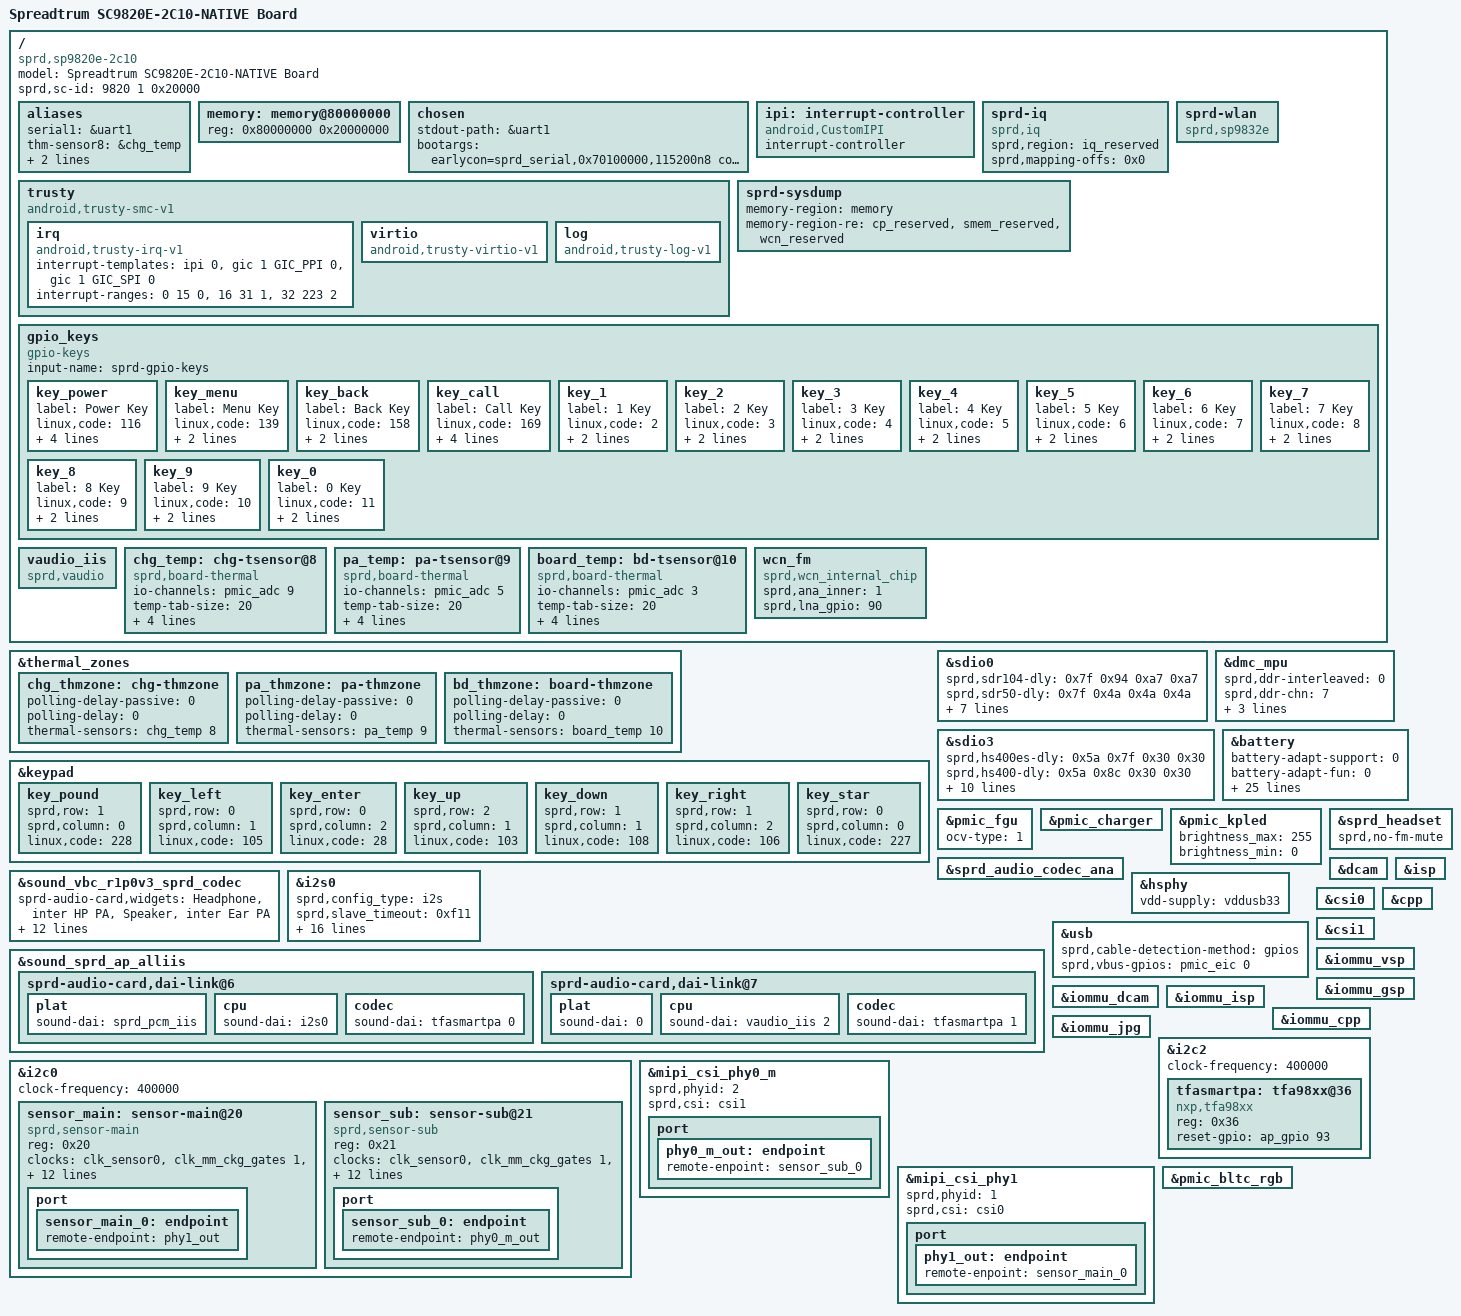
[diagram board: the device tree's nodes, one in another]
/*
 * Spreadtrum sharkle sp9820e board DTS file
 *
 * Copyright (C) 2017, Spreadtrum Communications Inc.
 *
 * This file is licensed under a dual GPLv2 or X11 license.
 */
/dts-v1/;

#include "sc9820e.dtsi"
#include "sp9820e-common.dtsi"

/ {
	model = "Spreadtrum SC9820E-2C10-NATIVE Board";

	compatible = "sprd,sp9820e-2c10", "sprd,sc9820e";

	sprd,sc-id = <9820 1 0x20000>;

	aliases {
		serial1 = &uart1;
		thm-sensor8 = &chg_temp;
		thm-sensor9 = &pa_temp;
		thm-sensor10 = &board_temp;
	};

	memory: memory@80000000 {
		device_type = "memory";
		reg = <0x80000000 0x20000000>;
	};

	chosen {
		stdout-path = &uart1;
		bootargs = "earlycon=sprd_serial,0x70100000,115200n8 console=ttyS1,115200n8 loglevel=1 init=/init root=/dev/ram0 rw androidboot.hardware=sp9820e_2c10";
	};

	ipi: interrupt-controller {
		compatible = "android,CustomIPI";
		#interrupt-cells = <1>;
		interrupt-controller;
	};

	trusty {
		compatible = "android,trusty-smc-v1";

		irq {
			compatible = "android,trusty-irq-v1";
			interrupt-templates = <&ipi 0>,
						<&gic 1 GIC_PPI 0>,
						<&gic 1 GIC_SPI 0>;
			interrupt-ranges = < 0  15 0>,
						<16  31 1>,
						<32 223 2>;
		};

		virtio {
			compatible = "android,trusty-virtio-v1";
		};

		log {
			compatible = "android,trusty-log-v1";
		};
	};

	sprd-iq {
		compatible = "sprd,iq";
		sprd,region = <&iq_reserved>;
		sprd,mapping-offs = <0x0>;
	};

	sprd-sysdump {
		memory-region = <&memory>;
		memory-region-re = <&cp_reserved>, <&smem_reserved>,
				   <&wcn_reserved>;
	};

	sprd-wlan {
		 compatible = "sprd,sp9832e";
	};

	gpio_keys {
		compatible = "gpio-keys";
		input-name = "sprd-gpio-keys";
		status = "ok";

		key_power {
			label = "Power Key";
			linux,code = <116>;
			gpios = <&pmic_eic 1 1>;
			debounce-interval = <5>;
			gpio-key,wakeup;
			gpio-key,level-trigger;
		};
		key_menu {
			label = "Menu Key";
			linux,code = <139>;
			gpios = <&ap_gpio 63 1>;
			gpio-key,wakeup;
		};
	
		key_back {
			label = "Back Key";
			linux,code = <158>;
			gpios = <&ap_gpio 145 1>;
			gpio-key,wakeup;
		};

		key_call {
			label = "Call Key";
			linux,code = <169>;
			gpios = <&pmic_eic 10 0>;
			debounce-interval = <5>;
			gpio-key,wakeup;
			gpio-key,level-trigger;
		};
		
		key_1 {
			label = "1 Key";
			linux,code = <2>;
			gpios = <&ap_gpio 72 1>;
			gpio-key,wakeup;
		};
		key_2 {
			label = "2 Key";
			linux,code = <3>;
			gpios = <&ap_gpio 156 1>;
			gpio-key,wakeup;
		};
		key_3 {
			label = "3 Key";
			linux,code = <4>;
			gpios = <&ap_gpio 144 1>;
			gpio-key,wakeup;
		};
		key_4 {
			label = "4 Key";
			linux,code = <5>;
			gpios = <&ap_gpio 73 1>;
			gpio-key,wakeup;
		};
		key_5 {
			label = "5 Key";
			linux,code = <6>;
			gpios = <&ap_gpio 154 1>;
			gpio-key,wakeup;
		};
	
		key_6 {
			label = "6 Key";
			linux,code = <7>;
			gpios = <&ap_gpio 4 1>;
			gpio-key,wakeup;
		};
		key_7 {
			label = "7 Key";
			linux,code = <8>;
			gpios = <&ap_gpio 138 1>;
			gpio-key,wakeup;
		};
		key_8 {
			label = "8 Key";
			linux,code = <9>;
			gpios = <&ap_gpio 155 1>;
			gpio-key,wakeup;
		};
		key_9 {
			label = "9 Key";
			linux,code = <10>;
			gpios = <&ap_gpio 5 1>;
			gpio-key,wakeup;
		};
		key_0 {
			label = "0 Key";
			linux,code = <11>;
			gpios = <&ap_gpio 137 1>;
			gpio-key,wakeup;
		};

	};

	vaudio_iis: vaudio_iis {
		compatible = "sprd,vaudio";
		#sound-dai-cells = <1>;
	};

	chg_temp:chg-tsensor@8 {
		compatible = "sprd,board-thermal";
		#thermal-sensor-cells = <1>;
		io-channels = <&pmic_adc 9>;
		io-channel-names = "adc_temp";
		temp-tab-size = <20>;
		temp-tab-val = <1094 1074 1050 1020 983 941 892
				838 779 717 654 590 528 468 413 362
				316 274 238 206>;
		temp-tab-temp = <750 800 850 900 950 1000 1050 1100
				 1150 1200 1250 1300 1350 1400 1450 1500
				 1550 1600 1650 1700>;
	};

	pa_temp:pa-tsensor@9 {
		compatible = "sprd,board-thermal";
		#thermal-sensor-cells = <1>;
		io-channels = <&pmic_adc 5>;
		io-channel-names = "adc_temp";
		temp-tab-size = <20>;
		temp-tab-val = <1094 1074 1050 1020 983 941 892
				838 779 717 654 590 528 468 413 362
				316 274 238 206>;
		temp-tab-temp = <750 800 850 900 950 1000 1050 1100
				 1150 1200 1250 1300 1350 1400 1450 1500
				 1550 1600 1650 1700>;
	};

	board_temp:bd-tsensor@10 {
		compatible = "sprd,board-thermal";
		#thermal-sensor-cells = <1>;
		io-channels = <&pmic_adc 3>;
		io-channel-names = "adc_temp";
		temp-tab-size = <20>;
		temp-tab-val = <1094 1074 1050 1020 983 941 892
				838 779 717 654 590 528 468 413 362
				316 274 238 206>;
		temp-tab-temp = <750 800 850 900 950 1000 1050 1100
				 1150 1200 1250 1300 1350 1400 1450 1500
				 1550 1600 1650 1700>;
	};//0 940mv 63 240mv  65 223mv 67 212mv

	wcn_fm {
		compatible = "sprd,wcn_internal_chip";
		sprd,ana_inner = <1>;
		sprd,lna_gpio = <90>;
	};
};

&thermal_zones{
		chg_thmzone: chg-thmzone {
			polling-delay-passive = <0>;
			polling-delay = <0>;
			thermal-sensors = <&chg_temp  8>;
		};

		pa_thmzone: pa-thmzone {
			polling-delay-passive = <0>;
			polling-delay = <0>;
			thermal-sensors = <&pa_temp  9>;
		};

		bd_thmzone: board-thmzone {
			polling-delay-passive = <0>;
			polling-delay = <0>;
			thermal-sensors = <&board_temp  10>;
		};
};

&keypad {
	status = "okay";
	key_pound {
		sprd,row = <1>;
		sprd,column = <0>;
		linux,code = <228>;
	};

	key_left {
		sprd,row = <0>;
		sprd,column = <1>;
		linux,code = <105>;
	};


	key_enter {
		sprd,row = <0>;
		sprd,column = <2>;
		linux,code = <28>;
	};

	key_up {
		sprd,row = <2>;
		sprd,column = <1>;
		linux,code = <103>;
	};

	key_down {
		sprd,row = <1>;
		sprd,column = <1>;
		linux,code = <108>;
	};

	key_right {
		sprd,row = <1>;
		sprd,column = <2>;
		linux,code = <106>;
	};
	key_star {
		sprd,row = <0>;
		sprd,column = <0>;
		linux,code = <227>;
	};
};

&sdio0 {
	sprd,sdr104-dly = <0x7f 0x94 0xa7 0xa7>;
	sprd,sdr50-dly = <0x7f 0x4a 0x4a 0x4a>;
	vmmc-supply = <&vddsdcore>;
	vqmmc-supply = <&vddsdio>;
	voltage-ranges = <3000 3000>;
	bus-width = <4>;
	sprd,name = "sdio_sd";
	no-sdio;
	no-mmc;
	status = "okay";
};

&dmc_mpu {
	sprd,ddr-interleaved = <0>;
	sprd,ddr-chn = <7>;
	chn-name = "MM", "GPU", "DISP",
		"A53", "AP/VSP/GSP", "WTLCP/PUBCP",
		"WCN/AON";
	memory-region = <&pub0_mpu_reserved>;
};

&sdio3 {
	sprd,hs400es-dly = <0x5a 0x7f 0x30 0x30>;
	sprd,hs400-dly = <0x5a 0x8c 0x30 0x30>;
	sprd,hs200-dly = <0x7f 0x8c 0x8e 0x8e>;
	sprd,ddr52-dly = <0x9f 0xB3 0x1e 0x1e>;
	vmmc-supply = <&vddemmccore>;
	voltage-ranges = <3000 3000>;
	bus-width = <8>;
	non-removable;
	cap-mmc-hw-reset;
	sprd,name = "sdio_emmc";
	no-sdio;
	no-sd;
	status = "okay";
};

&battery {
	battery-adapt-support = <0>;
	battery-adapt-fun = <0>;
	adp-cdp-cur = <450>;
	adp-dcp-cur = <700>;
	adp-sdp-cur = <450>;
	adp-unknown-cur = <450>;
	chg-end-vol = <4200>;
	chg-end-vol-check = <4180>;
	chg-bat-safety-vol = <4230>;
	rechg-vol = <4120>;
	rsense-real = <200>;
	rint = <206>;
	cnom = <1962>;
	ocv-tab-vol = <4164 4090  4042 3998 3959 3916 3883 
			3851 3819 3791 3772 3761 3751 3739
			3730 3694 3656 3607 3553 3501 3400>;
	ocv-tab-cap = <100  95   90   85   80   75   70
			65   60   55   50   45   40   35
			30   25   20   15   10   5   0>;
	temp-support = <1>;
	temp-tab-val = <1052 1043 970 860 790 690
			615 545 433 360 320 275
			236 200 172 147 132 110 100>;
	/* temperature + 1000,750 = 1000 + (-250)*/
	temp-tab-temp = <750 800 850 900 950 1000
			1050 1100 1150 1200 1250 1300
			1350 1400 1450 1500 1550 1600 1650>;
	jeita-temp-tab = <900 1000 1100 1450 1590>;
	jeita-temp-recovery-tab = <930 1030 1130 1420 1500>;
	jeita-cur-tab = <0 100 500 0x7fff 700 0>;
	jeita-cccv-tab = <4200 4200 4350 4350 4350 4350>;
};

&pmic_fgu {
	ocv-type = <1>;
};

&pmic_charger {
	status = "okay";
};

&pmic_kpled {
	 brightness_max = <255>;
	 brightness_min = <0>;
	 status = "okay";
};

&sprd_audio_codec_ana {
	status = "okay";
};

&sound_vbc_r1p0v3_sprd_codec {
	status = "okay";
	sprd-audio-card,widgets =
		"Headphone", "inter HP PA",
		"Speaker", "inter Ear PA";
	sprd-audio-card,routing =
		"HPMIC", "HP Mic Jack",
		"MIC", "Mic Jack",
		"AUXMIC", "Aux Mic Jack",
		"inter HP PA", "HP PA",
		"Ext Spk", "Spk PA",
		"inter Ear PA", "EAR",

		/* For vbc loopback */
		"Aud input", "AD Clk",
		"Aud input1", "AD Clk",
		"Aud input", "Digital ADCL Switch",
		"Aud input", "Digital ADCR Switch",
		"Aud input1", "Digital ADC1L Switch",
		"Aud input1", "Digital ADC1R Switch";
	/* ext_control_type, hook selection, mode, gpio share */
	sprd,spk-ext-pa-info = <0 0 2 0>;
	sprd,spk-ext-pa-gpio = <&ap_gpio 92 0>;
	sprd,spk-ext-pa-names = "ext_spk_r";
};

&i2s0 {
	status = "okay";

	sprd,config_type = "i2s";
	sprd,slave_timeout = <0xf11>;
	sprd,_hw_port = <0>;
	sprd,fs = <48000>;
	sprd,bus_type = <0>;
	sprd,rtx_mode = <3>;
	sprd,byte_per_chan = <1>;
	sprd,slave_mode = <0>;
	sprd,lsb = <0>;
	sprd,lrck = <1>; /*sync_mode*/
	sprd,low_for_left = <0>; /*lrck_inv*/
	sprd,clk_inv = <1>;
	sprd,pcm_short_frame = <0>; /*pcm_bus_mode*/
	sprd,pcm_slot = <0x1>;
	sprd,pcm_cycle = <1>;
	sprd,tx_watermark = <16>;
	sprd,rx_watermark = <16>;
	sprd,i2s_compatible= <1>;
};

&sound_sprd_ap_alliis {
	status = "okay";
	sprd-audio-card,dai-link@6 {
		plat {
			sound-dai = <&sprd_pcm_iis>;
		};
		cpu {
			sound-dai = <&i2s0>;
		};
		codec {
			sound-dai = <&tfasmartpa 0>;
		};
	};
	sprd-audio-card,dai-link@7 {
		plat {
			sound-dai = <0>;
		};
		cpu {
			/* Voice through nxp smart pa(a dummy dai) */
			sound-dai = <&vaudio_iis 2>;
		};
		codec {
			sound-dai = <&tfasmartpa 1>;
		};
	};
};

&sprd_headset {
	status = "okay";
	sprd,no-fm-mute;
};

&hsphy {
	vdd-supply = <&vddusb33>;
};

&usb {
	sprd,cable-detection-method = "gpios";
	sprd,vbus-gpios = <&pmic_eic 0 0>;
};

&dcam {
	status = "okay";
};

&isp {
	status = "okay";
};

&csi0 {
	status = "okay";
};

&cpp {
	status = "okay";
};

&csi1 {
	status = "okay";
};

&iommu_vsp {
	status = "okay";
};
&iommu_gsp {
	status = "okay";
};

&iommu_dcam {
	status = "okay";
};

&iommu_isp {
	status = "okay";
};

&iommu_cpp {
	status = "okay";
};

&iommu_jpg {
	status = "okay";
};

&i2c0 {
	status = "okay";
	clock-frequency = <400000>;

	sensor_main: sensor-main@20 {
		compatible = "sprd,sensor-main";
		reg = <0x20>;
		clock-names = "clk_src","sensor_eb",
			"clk_96m","clk_76m8",
			"clk_48m","clk_26m";
		clocks = <&clk_sensor0>, <&clk_mm_ckg_gates 1>,
			<&clk_twpll_96m>,<&clk_twpll_76m8>,
			<&clk_twpll_48m>,<&ext_26m>;
		vddio-supply = <&vddcamio>;
		vddcama-supply = <&vddcama>;
		vddcamd-supply = <&vddcamd>;
		vddcammot-supply = <&vddcammot>;
		reset-gpios = <&ap_gpio 44 0>;
		power-down-gpios = <&ap_gpio 46 0>;
		sensor-id0 = <&ap_gpio 74 1>;
		sensor-id1 = <&ap_gpio 60 1>;
		sensor-id2 = <&ap_gpio 62 1>;
		host = "dcam0";
		port {
			sensor_main_0: endpoint {
				remote-endpoint = <&phy1_out>;
			};
		};
	};
	sensor_sub: sensor-sub@21 {
		compatible = "sprd,sensor-sub";
		reg = <0x21>;
		clock-names = "clk_src","sensor_eb",
			"clk_96m","clk_76m8",
			"clk_48m","clk_26m";
		clocks = <&clk_sensor0>, <&clk_mm_ckg_gates 1>,
			<&clk_twpll_96m>,<&clk_twpll_76m8>,
			<&clk_twpll_48m>,<&ext_26m>;
		vddio-supply = <&vddcamio>;
		vddcama-supply = <&vddcama>;
		vddcamd-supply = <&vddcamd>;
		vddcammot-supply = <&vddcammot>;
		reset-gpios = <&ap_gpio 45 0>;
		power-down-gpios = <&ap_gpio 47 0>;
		sensor-id0 = <&ap_gpio 75 1>;
		sensor-id1 = <&ap_gpio 61 1>;
		sensor-id2 = <&ap_gpio 162 1>;
		host = "dcam1";
		port {
			sensor_sub_0: endpoint {
				remote-endpoint = <&phy0_m_out>;
			};
		};
	};
};

&i2c2 {
	status = "okay";
	clock-frequency = <400000>;

	tfasmartpa:tfa98xx@36 {
		compatible = "nxp,tfa98xx";
		#sound-dai-cells = <1>;
		reg = <0x36>;
		reset-gpio= <&ap_gpio 93 0>;
	};
	
};

&mipi_csi_phy0_m {
	status = "okay";
	sprd,phyid = <2>;
	sprd,csi = <&csi1>;
	port {
	phy0_m_out: endpoint {
		remote-enpoint = <&sensor_sub_0>;
		};
	};
};

&mipi_csi_phy1 {
	status = "okay";
	sprd,phyid = <1>;
	sprd,csi = <&csi0>;
	port {
	phy1_out: endpoint {
		remote-enpoint = <&sensor_main_0>;
		};
	};
};

&pmic_bltc_rgb {
	status = "okay";
};
